VERSION ""

NS_ :

BS_:

BO_ 262 STEERING_1: 5 OBDCAN3-11
 SG_ GEAR_SHIFTER : 4|2@0+ (1,0) [0|3] "" NEO
 SG_ STEER_WHEEL_ANGLE : 23|16@0- (0.0625,0) [-500|500] "deg"  NEO

BO_ 485 STEERING_2: 8 OBDCAN6-14
 SG_ STEER_WHEEL_ANGLE : 15|16@0- (0.0625,0) [-500|500] "deg" NEO
 SG_ STEER_WHEEL_SPEED : 27|12@0- (0.5,0) [-100|100] "tbd scale deg/s" NEO

BO_ 823 STEERING_3: 7 OBDCAN12-13
 SG_ USER_TORQUE_APPLIED : 9|1@0+ (1,0) [0|1] "" NEO
 SG_ STEER_WHEEL_ANGLE : 23|16@0- (0.0625,0) [-500|500] "deg"  NEO

BO_ 270794816 STEERING_SENSORS: 8 GMLAN
 SG_ STEER_WHEEL_ANGLE : 39|16@0- (0.0625,0) [-500|500] "deg"  NEO

BO_ 271368256 GEAR_SHIFTER: 8 GMLAN
 SG_ GEAR_SHIFTER : 17|2@0+ (1,0) [0|3] "" NEO

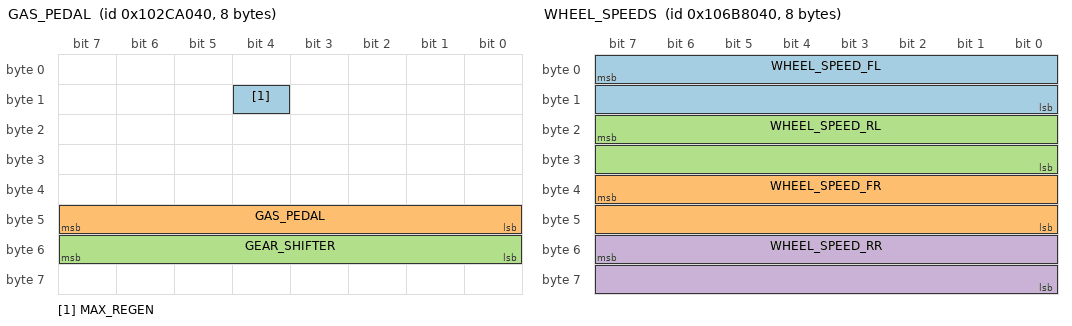
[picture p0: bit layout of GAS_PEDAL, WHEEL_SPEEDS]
BO_ 271360064 GAS_PEDAL: 8 GMLAN
 SG_ MAX_REGEN : 12|1@0+ (1,0) [0|1] "" NEO
 SG_ GAS_PEDAL : 47|8@0+ (1,0) [0|254] "" NEO
 SG_ GEAR_SHIFTER : 55|8@0+ (1,0) [0|255] "" NEO

BO_ 270860352 BRAKE_PEDAL: 2 GMLAN
 SG_ BRAKE_LEVEL : 2|2@0+ (1,0) [0|3] "" NEO
 SG_ BRAKE_SENSOR : 15|8@0+ (1,0) [0|255] "" NEO

BO_ 275480640 WHEEL_SPEEDS: 8 GMLAN
 SG_ WHEEL_SPEED_FL : 7|16@0+ (0.01,0) [0|70] "yd/s"  NEO
 SG_ WHEEL_SPEED_FR : 39|16@0+ (0.01,0) [0|70] "yd/s"  NEO
 SG_ WHEEL_SPEED_RL : 23|16@0+ (0.01,0) [0|70] "yd/s"  NEO
 SG_ WHEEL_SPEED_RR : 55|16@0+ (0.01,0) [0|70] "yd/s"  NEO

BO_ 270598208 LR_SPEEDS: 8 GMLAN
 SG_ CAR_SPEED_1 : 7|16@0+ (0.01,0) [0|100] "mph"  NEO
 SG_ CAR_SPEED_2 : 39|16@0+ (0.01,0) [0|100] "mph"  NEO

BO_ 276136000 ADAS_BUTTONS_1: 3 GMLAN
 SG_ CRUISE_BUTTONS : 3|4@0+ (1,0) [0|12] "" NEO

BO_ 276127808 ADAS_BUTTONS_2: 1 GMLAN
 SG_ LKAS_GAP_BUTTONS : 1|2@0+ (1,0) [0|2] "" NEO
